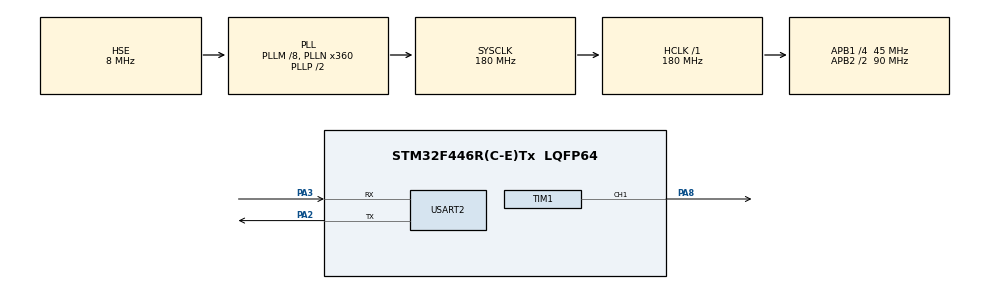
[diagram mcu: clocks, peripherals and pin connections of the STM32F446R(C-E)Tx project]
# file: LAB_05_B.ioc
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Dma.Request0=TIM1_CH1
Dma.TIM1_CH1.0.Direction=DMA_MEMORY_TO_PERIPH
Dma.TIM1_CH1.0.FIFOMode=DMA_FIFOMODE_DISABLE
Dma.TIM1_CH1.0.Instance=DMA2_Stream1
Dma.TIM1_CH1.0.MemDataAlignment=DMA_MDATAALIGN_HALFWORD
Dma.TIM1_CH1.0.MemInc=DMA_MINC_ENABLE
Dma.TIM1_CH1.0.Mode=DMA_NORMAL
Dma.TIM1_CH1.0.PeriphDataAlignment=DMA_PDATAALIGN_HALFWORD
Dma.TIM1_CH1.0.PeriphInc=DMA_PINC_DISABLE
Dma.TIM1_CH1.0.Priority=DMA_PRIORITY_HIGH
Mcu.Family=STM32F4
Mcu.Name=STM32F446R(C-E)Tx
Mcu.Package=LQFP64
NVIC.DMA2_Stream1_IRQn=true\:0\:0\:false\:false\:true\:false\:true\:true
NVIC.PriorityGroup=NVIC_PRIORITYGROUP_0
PA2.Mode=Asynchronous
PA2.Signal=USART2_TX
PA3.Mode=Asynchronous
PA3.Signal=USART2_RX
PA8.Signal=S_TIM1_CH1
PH0-OSC_IN.Mode=HSE-External-Oscillator
PH0-OSC_IN.Signal=RCC_OSC_IN
PH1-OSC_OUT.Mode=HSE-External-Oscillator
PH1-OSC_OUT.Signal=RCC_OSC_OUT
ProjectManager.HeapSize=0x200
ProjectManager.StackSize=0x400
ProjectManager.TargetToolchain=STM32CubeIDE
RCC.AHBFreq_Value=180000000
RCC.APB1CLKDivider=RCC_HCLK_DIV4
RCC.APB1Freq_Value=45000000
RCC.APB1TimFreq_Value=90000000
RCC.APB2CLKDivider=RCC_HCLK_DIV2
RCC.APB2Freq_Value=90000000
RCC.APB2TimFreq_Value=180000000
RCC.CortexFreq_Value=180000000
RCC.FLatency-AdvancedSettings=FLASH_LATENCY_5
RCC.HCLKFreq_Value=180000000
RCC.HSE_VALUE=8000000
RCC.HSI_VALUE=16000000
RCC.LSE_VALUE=32768
RCC.PLLM=8
RCC.PLLN=360
RCC.PLLSourceVirtual=RCC_PLLSOURCE_HSE
RCC.SYSCLKFreq_VALUE=180000000
RCC.SYSCLKSource=RCC_SYSCLKSOURCE_PLLCLK
RCC.USBFreq_Value=180000000
RCC.VCOOutputFreq_Value=360000000
SH.S_TIM1_CH1.0=TIM1_CH1,PWM Generation1 CH1
TIM1.Channel-PWM\ Generation1\ CH1=TIM_CHANNEL_1
TIM1.Period=224
USART2.VirtualMode=VM_ASYNC
VP_TIM1_VS_ClockSourceINT.Mode=Internal
VP_TIM6_VS_ClockSourceINT.Mode=Enable_Timer
board=NUCLEO-F446RE

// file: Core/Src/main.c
/* USER CODE BEGIN Header */
/**
  ******************************************************************************
  * @file           : main.c
  * @brief          : Main program body
  ******************************************************************************
  * @attention
  *
  * Copyright (c) 2026 STMicroelectronics.
  * All rights reserved.
  *
  * This software is licensed under terms that can be found in the LICENSE file
  * in the root directory of this software component.
  * If no LICENSE file comes with this software, it is provided AS-IS.
  *
  ******************************************************************************
  */
/* USER CODE END Header */
#include "main.h"

/* USER CODE BEGIN Includes */

#define WS_ARR      224U
#define WS_T1H      144U
#define WS_T0H       72U
#define WS_RESET     50U
#define NUM_LEDS      5U
#define PWM_BUF_SIZE  ((NUM_LEDS * 24U) + WS_RESET)

typedef struct {
	uint8_t r,g,b;
} LED_t;

static LED_t g_leds[NUM_LEDS];
static uint16_t pwmData[PWM_BUF_SIZE];
static volatile uint8_t datasentflag = 0;

/* USER CODE END Includes */

TIM_HandleTypeDef htim1;
TIM_HandleTypeDef htim6;
DMA_HandleTypeDef hdma_tim1_ch1;

UART_HandleTypeDef huart2;

void SystemClock_Config(void);
static void MX_GPIO_Init(void);
static void MX_DMA_Init(void);
static void MX_TIM1_Init(void);
static void MX_TIM6_Init(void);
static void MX_USART2_UART_Init(void);

/* USER CODE BEGIN 0 */

void WS2812B_Send(void) {
    uint32_t idx = 0;
    for (uint32_t led = 0; led < NUM_LEDS; led++) {
        uint32_t color = ((uint32_t)g_leds[led].g << 16) |
                         ((uint32_t)g_leds[led].r << 8) |
                          (uint32_t)g_leds[led].b;
        for (int bit = 23; bit >= 0; bit--)
            pwmData[idx++] = (color & (1U << bit)) ? WS_T1H : WS_T0H;
    }
    for (uint32_t i = 0; i < WS_RESET; i++) pwmData[idx++] = 0U;

    datasentflag = 0;
    HAL_TIM_PWM_Start_DMA(&htim1, TIM_CHANNEL_1, (uint32_t*)pwmData, idx);
    while (!datasentflag) {}
}

void WS2812_SetAll(uint8_t r, uint8_t g, uint8_t b) {
    for (uint32_t i = 0; i < NUM_LEDS; i++) g_leds[i] = (LED_t){r,g,b};
    WS2812B_Send();
}

void WS2812_SetHue(uint16_t H) {
    H %= 360U;
    uint8_t seg = H/60U, frac = H%60U;
    uint8_t q = 255U*(60U-frac)/60U, t = 255U*frac/60U;
    uint8_t r,g,b;
    switch(seg) {
        case 0: r=255; g=t;   b=0;   break;
        case 1: r=q;   g=255; b=0;   break;
        case 2: r=0;   g=255; b=t;   break;
        case 3: r=0;   g=q;   b=255; break;
        case 4: r=t;   g=0;   b=255; break;
        case 5: r=255; g=0;   b=q;   break;
        default: r=g=b=0; break;
    }
    WS2812_SetAll(r,g,b);
}

void UART_SendString(const char *s) {
    HAL_UART_Transmit(&huart2, (uint8_t*)s, strlen(s), HAL_MAX_DELAY);
}

/* USER CODE END 0 */

int main(void)
{

  /* MCU Configuration--------------------------------------------------------*/

  /* Reset of all peripherals, Initializes the Flash interface and the Systick. */
  HAL_Init();

  /* Configure the system clock */
  SystemClock_Config();

  /* Initialize all configured peripherals */
  MX_GPIO_Init();
  MX_DMA_Init();
  MX_TIM1_Init();
  MX_TIM6_Init();
  MX_USART2_UART_Init();
  /* USER CODE BEGIN 2 */

  UART_SendString("LAB 05 (HAL): WS2812B LED Strip Lighting\r\n");

  // Clear LEDs initially
  WS2812_SetAll(0,0,0);
  HAL_Delay(100);

  // Task 01: Palette demo
  UART_SendString("[Task 01] Colour palette — 1 s per colour\r\n");
  for (uint32_t i=0;i<PALETTE_COUNT;i++) {
      WS2812_SetAll(palette[i].r,palette[i].g,palette[i].b);
      char buf[128];
      sprintf(buf,"Colour: %-12s R=%3u G=%3u B=%3u\r\n",
              palette[i].name,palette[i].r,palette[i].g,palette[i].b);
      UART_SendString(buf);
      HAL_Delay(1000);
  }

  char buf[180];
  uint32_t sequence_number = 1;

  UART_SendString("\r\n[Task 02] 46 Step LED Sequence\r\n");
  UART_SendString(" n |    LED1    |    LED2    |    LED3    |    LED4    |    LED5   \r\n");

  for (uint32_t color = 0; color < 9; color++) {
	  for (uint32_t led = 0; led < NUM_LEDS; led++) {
		  WS2812_ShowOneLed(led,
							palette[color].r,
							palette[color].g,
							palette[color].b);

		  snprintf(buf,sizeof(buf),
				   "%-2lu | %-10s | %-10s | %-10s | %-10s | %-10s\r\n",
				   (unsigned long)sequence_number,
				   (led == 0) ? palette[color].name : "0",
				   (led == 1) ? palette[color].name : "0",
				   (led == 2) ? palette[color].name : "0",
				   (led == 3) ? palette[color].name : "0",
				   (led == 4) ? palette[color].name : "0");

		  UART_SendString(buf);
		  sequence_number++;
		  HAL_Delay(SEQ_VISIBLE_DELAY_MS);
	  }
  }

  WS2812_SetAll(0,0,0);
  snprintf(buf,sizeof(buf),
		   "%lu | ---------- | ---------- | ---------- | ---------- | ---------- \r\n",
		   (unsigned long)sequence_number);
  UART_SendString(buf);
  HAL_Delay(SEQ_END_OFF_DELAY_MS);

  UART_SendString("46 step sequence complete. Final OFF delay = 2s\r\n");
  UART_SendString("\r\n[Task 03] Hue sweep 0‑359 (step 3, 25 ms)\r\n");

  /* USER CODE END 2 */

  /* Infinite loop */
  while (1)
  {

	for (uint16_t h=0;h<360;h+=3)
	{
	  WS2812_SetHue(h);
	  HAL_Delay(25);
    }
    UART_SendString("Hue sweep repeat\r\n");

  }
}

void SystemClock_Config(void)
{
  RCC_OscInitTypeDef RCC_OscInitStruct = {0};
  RCC_ClkInitTypeDef RCC_ClkInitStruct = {0};

  /** Configure the main internal regulator output voltage
  */
  __HAL_RCC_PWR_CLK_ENABLE();
  __HAL_PWR_VOLTAGESCALING_CONFIG(PWR_REGULATOR_VOLTAGE_SCALE1);

  /** Initializes the RCC Oscillators according to the specified parameters
  * in the RCC_OscInitTypeDef structure.
  */
  RCC_OscInitStruct.OscillatorType = RCC_OSCILLATORTYPE_HSE;
  RCC_OscInitStruct.HSEState = RCC_HSE_ON;
  RCC_OscInitStruct.PLL.PLLState = RCC_PLL_ON;
  RCC_OscInitStruct.PLL.PLLSource = RCC_PLLSOURCE_HSE;
  RCC_OscInitStruct.PLL.PLLM = 8;
  RCC_OscInitStruct.PLL.PLLN = 360;
  RCC_OscInitStruct.PLL.PLLP = RCC_PLLP_DIV2;
  RCC_OscInitStruct.PLL.PLLQ = 2;
  RCC_OscInitStruct.PLL.PLLR = 2;
  if (HAL_RCC_OscConfig(&RCC_OscInitStruct) != HAL_OK)
  {
    Error_Handler();
  }

  /** Activate the Over-Drive mode
  */
  if (HAL_PWREx_EnableOverDrive() != HAL_OK)
  {
    Error_Handler();
  }

  /** Initializes the CPU, AHB and APB buses clocks
  */
  RCC_ClkInitStruct.ClockType = RCC_CLOCKTYPE_HCLK|RCC_CLOCKTYPE_SYSCLK
                              |RCC_CLOCKTYPE_PCLK1|RCC_CLOCKTYPE_PCLK2;
  RCC_ClkInitStruct.SYSCLKSource = RCC_SYSCLKSOURCE_PLLCLK;
  RCC_ClkInitStruct.AHBCLKDivider = RCC_SYSCLK_DIV1;
  RCC_ClkInitStruct.APB1CLKDivider = RCC_HCLK_DIV4;
  RCC_ClkInitStruct.APB2CLKDivider = RCC_HCLK_DIV2;

  if (HAL_RCC_ClockConfig(&RCC_ClkInitStruct, FLASH_LATENCY_5) != HAL_OK)
  {
    Error_Handler();
  }
}

static void MX_TIM1_Init(void)
{

  TIM_ClockConfigTypeDef sClockSourceConfig = {0};
  TIM_MasterConfigTypeDef sMasterConfig = {0};
  TIM_OC_InitTypeDef sConfigOC = {0};
  TIM_BreakDeadTimeConfigTypeDef sBreakDeadTimeConfig = {0};

  htim1.Instance = TIM1;
  htim1.Init.Prescaler = 0;
  htim1.Init.CounterMode = TIM_COUNTERMODE_UP;
  htim1.Init.Period = 224;
  htim1.Init.ClockDivision = TIM_CLOCKDIVISION_DIV1;
  htim1.Init.RepetitionCounter = 0;
  htim1.Init.AutoReloadPreload = TIM_AUTORELOAD_PRELOAD_DISABLE;
  if (HAL_TIM_Base_Init(&htim1) != HAL_OK)
  {
    Error_Handler();
  }
  sClockSourceConfig.ClockSource = TIM_CLOCKSOURCE_INTERNAL;
  if (HAL_TIM_ConfigClockSource(&htim1, &sClockSourceConfig) != HAL_OK)
  {
    Error_Handler();
  }
  if (HAL_TIM_PWM_Init(&htim1) != HAL_OK)
  {
    Error_Handler();
  }
  sMasterConfig.MasterOutputTrigger = TIM_TRGO_RESET;
  sMasterConfig.MasterSlaveMode = TIM_MASTERSLAVEMODE_DISABLE;
  if (HAL_TIMEx_MasterConfigSynchronization(&htim1, &sMasterConfig) != HAL_OK)
  {
    Error_Handler();
  }
  sConfigOC.OCMode = TIM_OCMODE_PWM1;
  sConfigOC.Pulse = 0;
  sConfigOC.OCPolarity = TIM_OCPOLARITY_HIGH;
  sConfigOC.OCNPolarity = TIM_OCNPOLARITY_HIGH;
  sConfigOC.OCFastMode = TIM_OCFAST_DISABLE;
  sConfigOC.OCIdleState = TIM_OCIDLESTATE_RESET;
  sConfigOC.OCNIdleState = TIM_OCNIDLESTATE_RESET;
  if (HAL_TIM_PWM_ConfigChannel(&htim1, &sConfigOC, TIM_CHANNEL_1) != HAL_OK)
  {
    Error_Handler();
  }
  sBreakDeadTimeConfig.OffStateRunMode = TIM_OSSR_DISABLE;
  sBreakDeadTimeConfig.OffStateIDLEMode = TIM_OSSI_DISABLE;
  sBreakDeadTimeConfig.LockLevel = TIM_LOCKLEVEL_OFF;
  sBreakDeadTimeConfig.DeadTime = 0;
  sBreakDeadTimeConfig.BreakState = TIM_BREAK_DISABLE;
  sBreakDeadTimeConfig.BreakPolarity = TIM_BREAKPOLARITY_HIGH;
  sBreakDeadTimeConfig.AutomaticOutput = TIM_AUTOMATICOUTPUT_DISABLE;
  if (HAL_TIMEx_ConfigBreakDeadTime(&htim1, &sBreakDeadTimeConfig) != HAL_OK)
  {
    Error_Handler();
  }
  HAL_TIM_MspPostInit(&htim1);

}

static void MX_TIM6_Init(void)
{

  TIM_MasterConfigTypeDef sMasterConfig = {0};

  htim6.Instance = TIM6;
  htim6.Init.Prescaler = 0;
  htim6.Init.CounterMode = TIM_COUNTERMODE_UP;
  htim6.Init.Period = 65535;
  htim6.Init.AutoReloadPreload = TIM_AUTORELOAD_PRELOAD_DISABLE;
  if (HAL_TIM_Base_Init(&htim6) != HAL_OK)
  {
    Error_Handler();
  }
  sMasterConfig.MasterOutputTrigger = TIM_TRGO_RESET;
  sMasterConfig.MasterSlaveMode = TIM_MASTERSLAVEMODE_DISABLE;
  if (HAL_TIMEx_MasterConfigSynchronization(&htim6, &sMasterConfig) != HAL_OK)
  {
    Error_Handler();
  }

}

static void MX_USART2_UART_Init(void)
{

  huart2.Instance = USART2;
  huart2.Init.BaudRate = 115200;
  huart2.Init.WordLength = UART_WORDLENGTH_8B;
  huart2.Init.StopBits = UART_STOPBITS_1;
  huart2.Init.Parity = UART_PARITY_NONE;
  huart2.Init.Mode = UART_MODE_TX_RX;
  huart2.Init.HwFlowCtl = UART_HWCONTROL_NONE;
  huart2.Init.OverSampling = UART_OVERSAMPLING_16;
  if (HAL_UART_Init(&huart2) != HAL_OK)
  {
    Error_Handler();
  }

}

static void MX_DMA_Init(void)
{

  /* DMA controller clock enable */
  __HAL_RCC_DMA2_CLK_ENABLE();

  /* DMA interrupt init */
  /* DMA2_Stream1_IRQn interrupt configuration */
  HAL_NVIC_SetPriority(DMA2_Stream1_IRQn, 0, 0);
  HAL_NVIC_EnableIRQ(DMA2_Stream1_IRQn);

}

static void MX_GPIO_Init(void)
{

  /* GPIO Ports Clock Enable */
  __HAL_RCC_GPIOH_CLK_ENABLE();
  __HAL_RCC_GPIOA_CLK_ENABLE();

}

/* USER CODE BEGIN 4 */

void HAL_TIM_PWM_PulseFinishedCallback(TIM_HandleTypeDef *htim) {
    if (htim->Instance == TIM1) {
        HAL_TIM_PWM_Stop_DMA(&htim1, TIM_CHANNEL_1);
        datasentflag = 1;
    }
}

/* USER CODE END 4 */

void Error_Handler(void)
{
  __disable_irq();
  while (1)
  {
  }
}
